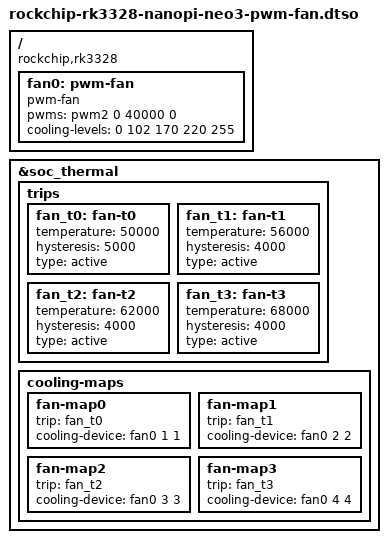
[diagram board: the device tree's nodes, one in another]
/dts-v1/;
/plugin/;

/*
 * NanoPi NEO3 onboard fan connector (CON4, 2-pin JST ZH 1.5mm, 5V).
 * CON4 is switched from VDD_5V by an AO3415A P-FET driven via a 2N7002
 * from RK3328 PWM2 / GPIO2_A6 (schematic sheet 11, "FAN"), so PWM duty
 * controls fan speed. Registers a pwm-fan cooling device on the SoC
 * thermal zone: 40% at 50C stepping up to 100% at 68C, off below 45C.
 */

/ {
	compatible = "rockchip,rk3328";

	fragment@0 {
		target-path = "/";
		__overlay__ {
			fan0: pwm-fan {
				compatible = "pwm-fan";
				pwms = <&pwm2 0 40000 0>;
				cooling-levels = <0 102 170 220 255>;
				#cooling-cells = <2>;
			};
		};
	};

	fragment@1 {
		target = <&soc_thermal>;
		__overlay__ {
			trips {
				fan_t0: fan-t0 { temperature = <50000>; hysteresis = <5000>; type = "active"; };
				fan_t1: fan-t1 { temperature = <56000>; hysteresis = <4000>; type = "active"; };
				fan_t2: fan-t2 { temperature = <62000>; hysteresis = <4000>; type = "active"; };
				fan_t3: fan-t3 { temperature = <68000>; hysteresis = <4000>; type = "active"; };
			};
			cooling-maps {
				fan-map0 { trip = <&fan_t0>; cooling-device = <&fan0 1 1>; };
				fan-map1 { trip = <&fan_t1>; cooling-device = <&fan0 2 2>; };
				fan-map2 { trip = <&fan_t2>; cooling-device = <&fan0 3 3>; };
				fan-map3 { trip = <&fan_t3>; cooling-device = <&fan0 4 4>; };
			};
		};
	};
};
